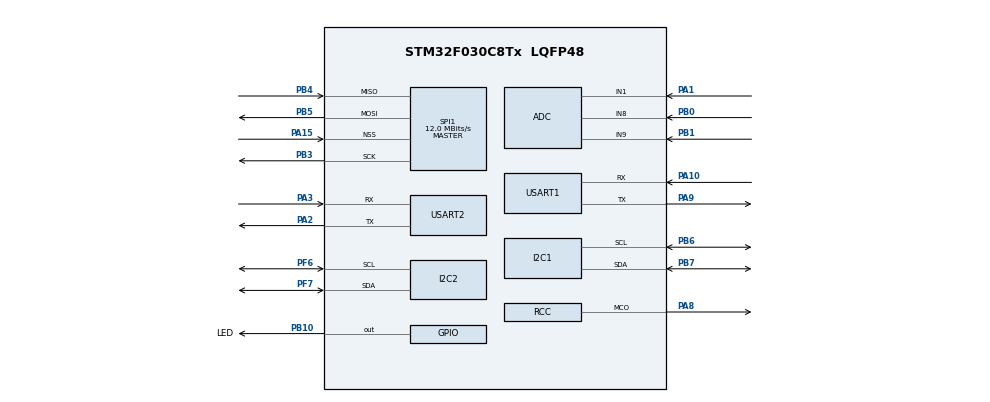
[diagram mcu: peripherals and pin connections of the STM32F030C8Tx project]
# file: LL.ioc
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I2C2.Timing=0x20303E5D
Mcu.Family=STM32F0
Mcu.Name=STM32F030C8Tx
Mcu.Package=LQFP48
PA1.Mode=IN1
PA1.Signal=ADC_IN1
PA10.Mode=Asynchronous
PA10.Signal=USART1_RX
PA13.Mode=Serial_Wire
PA13.Signal=SYS_SWDIO
PA14.Mode=Serial_Wire
PA14.Signal=SYS_SWCLK
PA15.Mode=NSS_Signal_Hard_Input
PA15.Signal=SPI1_NSS
PA2.Mode=Asynchronous
PA2.Signal=USART2_TX
PA3.Mode=Asynchronous
PA3.Signal=USART2_RX
PA8.Mode=Clock-out
PA8.Signal=RCC_MCO
PA9.Mode=Asynchronous
PA9.Signal=USART1_TX
PB0.Mode=IN8
PB0.Signal=ADC_IN8
PB1.Mode=IN9
PB1.Signal=ADC_IN9
PB10.GPIO_Label=LED
PB10.Signal=GPIO_Output
PB3.Mode=Full_Duplex_Master
PB3.Signal=SPI1_SCK
PB4.Mode=Full_Duplex_Master
PB4.Signal=SPI1_MISO
PB5.Mode=Full_Duplex_Master
PB5.Signal=SPI1_MOSI
PB6.Mode=I2C
PB6.Signal=I2C1_SCL
PB7.Mode=I2C
PB7.Signal=I2C1_SDA
PF0-OSC_IN.Mode=HSE-External-Oscillator
PF0-OSC_IN.Signal=RCC_OSC_IN
PF1-OSC_OUT.Mode=HSE-External-Oscillator
PF1-OSC_OUT.Signal=RCC_OSC_OUT
PF6.Mode=I2C
PF6.Signal=I2C2_SCL
PF7.Mode=I2C
PF7.Signal=I2C2_SDA
ProjectManager.HeapSize=0x200
ProjectManager.StackSize=0x400
ProjectManager.TargetToolchain=TrueSTUDIO
RCC.AHBFreq_Value=48000000
RCC.APB1Freq_Value=48000000
RCC.APB1TimFreq_Value=48000000
RCC.HCLKFreq_Value=48000000
RCC.PLLMUL=RCC_PLL_MUL12
RCC.RCC_MCOSource=RCC_MCO1SOURCE_PLLCLK_DIV2
RCC.SYSCLKFreq_VALUE=48000000
RCC.SYSCLKSource=RCC_SYSCLKSOURCE_PLLCLK
SPI1.BaudRatePrescaler=SPI_BAUDRATEPRESCALER_4
SPI1.CalculateBaudRate=12.0 MBits/s
SPI1.Direction=SPI_DIRECTION_2LINES
SPI1.Mode=SPI_MODE_MASTER
SPI1.VirtualNSS=VM_NSSHARD
SPI1.VirtualType=VM_MASTER
USART1.VirtualMode-Asynchronous=VM_ASYNC
USART2.VirtualMode-Asynchronous=VM_ASYNC
board=custom

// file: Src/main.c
/* USER CODE BEGIN Header */
/**
  ******************************************************************************
  * @file           : main.c
  * @brief          : Main program body
  ******************************************************************************
  * @attention
  *
  * <h2><center>&copy; Copyright (c) 2019 STMicroelectronics.
  * All rights reserved.</center></h2>
  *
  * This software component is licensed by ST under BSD 3-Clause license,
  * the "License"; You may not use this file except in compliance with the
  * License. You may obtain a copy of the License at:
  *                        opensource.org/licenses/BSD-3-Clause
  *
  ******************************************************************************
  */
/* USER CODE END Header */

#include "main.h"

void SystemClock_Config(void);
static void MX_GPIO_Init(void);
static void MX_ADC_Init(void);
static void MX_I2C1_Init(void);
static void MX_I2C2_Init(void);
static void MX_SPI1_Init(void);
static void MX_USART1_UART_Init(void);
static void MX_USART2_UART_Init(void);

int main(void)
{

  /* MCU Configuration--------------------------------------------------------*/

  /* Reset of all peripherals, Initializes the Flash interface and the Systick. */

  LL_APB1_GRP2_EnableClock(LL_APB1_GRP2_PERIPH_SYSCFG);
  LL_APB1_GRP1_EnableClock(LL_APB1_GRP1_PERIPH_PWR);

  /* System interrupt init*/

  /* Configure the system clock */
  SystemClock_Config();

  /* Initialize all configured peripherals */
  MX_GPIO_Init();
  MX_ADC_Init();
  MX_I2C1_Init();
  MX_I2C2_Init();
  MX_SPI1_Init();
  MX_USART1_UART_Init();
  MX_USART2_UART_Init();

  /* Infinite loop */
  while (1)
  {

    /* USER CODE BEGIN 3 */
	LL_GPIO_TogglePin(LED_GPIO_Port, LED_Pin);
	/* Insert delay 1000 ms */
	LL_mDelay(1000);
  }
  /* USER CODE END 3 */
}

void SystemClock_Config(void)
{
  LL_FLASH_SetLatency(LL_FLASH_LATENCY_1);

  if(LL_FLASH_GetLatency() != LL_FLASH_LATENCY_1)
  {
  Error_Handler();
  }
  LL_RCC_HSI_Enable();

   /* Wait till HSI is ready */
  while(LL_RCC_HSI_IsReady() != 1)
  {

  }
  LL_RCC_HSI_SetCalibTrimming(16);
  LL_RCC_HSI14_Enable();

   /* Wait till HSI14 is ready */
  while(LL_RCC_HSI14_IsReady() != 1)
  {

  }
  LL_RCC_HSI14_SetCalibTrimming(16);
  LL_RCC_PLL_ConfigDomain_SYS(LL_RCC_PLLSOURCE_HSI_DIV_2, LL_RCC_PLL_MUL_12);
  LL_RCC_PLL_Enable();

   /* Wait till PLL is ready */
  while(LL_RCC_PLL_IsReady() != 1)
  {

  }
  LL_RCC_SetAHBPrescaler(LL_RCC_SYSCLK_DIV_1);
  LL_RCC_SetAPB1Prescaler(LL_RCC_APB1_DIV_1);
  LL_RCC_SetSysClkSource(LL_RCC_SYS_CLKSOURCE_PLL);

   /* Wait till System clock is ready */
  while(LL_RCC_GetSysClkSource() != LL_RCC_SYS_CLKSOURCE_STATUS_PLL)
  {

  }
  LL_Init1msTick(48000000);
  LL_SYSTICK_SetClkSource(LL_SYSTICK_CLKSOURCE_HCLK);
  LL_SetSystemCoreClock(48000000);
  LL_RCC_HSI14_EnableADCControl();
  LL_RCC_SetUSARTClockSource(LL_RCC_USART1_CLKSOURCE_PCLK1);
  LL_RCC_SetI2CClockSource(LL_RCC_I2C1_CLKSOURCE_HSI);
  LL_RCC_ConfigMCO(LL_RCC_MCO1SOURCE_PLLCLK_DIV_2, LL_RCC_MCO1_DIV_1);
}

static void MX_ADC_Init(void)
{

  LL_ADC_InitTypeDef ADC_InitStruct = {0};
  LL_ADC_REG_InitTypeDef ADC_REG_InitStruct = {0};

  LL_GPIO_InitTypeDef GPIO_InitStruct = {0};

  /* Peripheral clock enable */
  LL_APB1_GRP2_EnableClock(LL_APB1_GRP2_PERIPH_ADC1);

  LL_AHB1_GRP1_EnableClock(LL_AHB1_GRP1_PERIPH_GPIOA);
  LL_AHB1_GRP1_EnableClock(LL_AHB1_GRP1_PERIPH_GPIOB);
  /**ADC GPIO Configuration
  PA1   ------> ADC_IN1
  PB0   ------> ADC_IN8
  PB1   ------> ADC_IN9
  */
  GPIO_InitStruct.Pin = LL_GPIO_PIN_1;
  GPIO_InitStruct.Mode = LL_GPIO_MODE_ANALOG;
  GPIO_InitStruct.Pull = LL_GPIO_PULL_NO;
  LL_GPIO_Init(GPIOA, &GPIO_InitStruct);

  GPIO_InitStruct.Pin = LL_GPIO_PIN_0;
  GPIO_InitStruct.Mode = LL_GPIO_MODE_ANALOG;
  GPIO_InitStruct.Pull = LL_GPIO_PULL_NO;
  LL_GPIO_Init(GPIOB, &GPIO_InitStruct);

  GPIO_InitStruct.Pin = LL_GPIO_PIN_1;
  GPIO_InitStruct.Mode = LL_GPIO_MODE_ANALOG;
  GPIO_InitStruct.Pull = LL_GPIO_PULL_NO;
  LL_GPIO_Init(GPIOB, &GPIO_InitStruct);

  /** Configure Regular Channel
  */
  LL_ADC_REG_SetSequencerChAdd(ADC1, LL_ADC_CHANNEL_1);
  /** Configure Regular Channel
  */
  LL_ADC_REG_SetSequencerChAdd(ADC1, LL_ADC_CHANNEL_8);
  /** Configure Regular Channel
  */
  LL_ADC_REG_SetSequencerChAdd(ADC1, LL_ADC_CHANNEL_9);
  /** Configure the global features of the ADC (Clock, Resolution, Data Alignment and number of conversion)
  */
  ADC_InitStruct.Clock = LL_ADC_CLOCK_ASYNC;
  ADC_InitStruct.Resolution = LL_ADC_RESOLUTION_12B;
  ADC_InitStruct.DataAlignment = LL_ADC_DATA_ALIGN_RIGHT;
  ADC_InitStruct.LowPowerMode = LL_ADC_LP_MODE_NONE;
  LL_ADC_Init(ADC1, &ADC_InitStruct);
  ADC_REG_InitStruct.TriggerSource = LL_ADC_REG_TRIG_SOFTWARE;
  ADC_REG_InitStruct.SequencerDiscont = LL_ADC_REG_SEQ_DISCONT_DISABLE;
  ADC_REG_InitStruct.ContinuousMode = LL_ADC_REG_CONV_SINGLE;
  ADC_REG_InitStruct.DMATransfer = LL_ADC_REG_DMA_TRANSFER_LIMITED;
  ADC_REG_InitStruct.Overrun = LL_ADC_REG_OVR_DATA_PRESERVED;
  LL_ADC_REG_Init(ADC1, &ADC_REG_InitStruct);
  LL_ADC_REG_SetSequencerScanDirection(ADC1, LL_ADC_REG_SEQ_SCAN_DIR_FORWARD);
  LL_ADC_SetSamplingTimeCommonChannels(ADC1, LL_ADC_SAMPLINGTIME_1CYCLE_5);
  LL_ADC_DisableIT_EOC(ADC1);
  LL_ADC_DisableIT_EOS(ADC1);

}

static void MX_I2C1_Init(void)
{

  LL_I2C_InitTypeDef I2C_InitStruct = {0};

  LL_GPIO_InitTypeDef GPIO_InitStruct = {0};

  LL_AHB1_GRP1_EnableClock(LL_AHB1_GRP1_PERIPH_GPIOB);
  /**I2C1 GPIO Configuration
  PB6   ------> I2C1_SCL
  PB7   ------> I2C1_SDA
  */
  GPIO_InitStruct.Pin = LL_GPIO_PIN_6;
  GPIO_InitStruct.Mode = LL_GPIO_MODE_ALTERNATE;
  GPIO_InitStruct.Speed = LL_GPIO_SPEED_FREQ_HIGH;
  GPIO_InitStruct.OutputType = LL_GPIO_OUTPUT_OPENDRAIN;
  GPIO_InitStruct.Pull = LL_GPIO_PULL_UP;
  GPIO_InitStruct.Alternate = LL_GPIO_AF_1;
  LL_GPIO_Init(GPIOB, &GPIO_InitStruct);

  GPIO_InitStruct.Pin = LL_GPIO_PIN_7;
  GPIO_InitStruct.Mode = LL_GPIO_MODE_ALTERNATE;
  GPIO_InitStruct.Speed = LL_GPIO_SPEED_FREQ_HIGH;
  GPIO_InitStruct.OutputType = LL_GPIO_OUTPUT_OPENDRAIN;
  GPIO_InitStruct.Pull = LL_GPIO_PULL_UP;
  GPIO_InitStruct.Alternate = LL_GPIO_AF_1;
  LL_GPIO_Init(GPIOB, &GPIO_InitStruct);

  /* Peripheral clock enable */
  LL_APB1_GRP1_EnableClock(LL_APB1_GRP1_PERIPH_I2C1);

  /** I2C Initialization
  */
  LL_I2C_DisableOwnAddress2(I2C1);
  LL_I2C_DisableGeneralCall(I2C1);
  LL_I2C_EnableClockStretching(I2C1);
  I2C_InitStruct.PeripheralMode = LL_I2C_MODE_I2C;
  I2C_InitStruct.Timing = 0x2000090E;
  I2C_InitStruct.AnalogFilter = LL_I2C_ANALOGFILTER_ENABLE;
  I2C_InitStruct.DigitalFilter = 0;
  I2C_InitStruct.OwnAddress1 = 0;
  I2C_InitStruct.TypeAcknowledge = LL_I2C_ACK;
  I2C_InitStruct.OwnAddrSize = LL_I2C_OWNADDRESS1_7BIT;
  LL_I2C_Init(I2C1, &I2C_InitStruct);
  LL_I2C_EnableAutoEndMode(I2C1);
  LL_I2C_SetOwnAddress2(I2C1, 0, LL_I2C_OWNADDRESS2_NOMASK);

}

static void MX_I2C2_Init(void)
{

  LL_I2C_InitTypeDef I2C_InitStruct = {0};

  LL_GPIO_InitTypeDef GPIO_InitStruct = {0};

  LL_AHB1_GRP1_EnableClock(LL_AHB1_GRP1_PERIPH_GPIOF);
  /**I2C2 GPIO Configuration
  PF6   ------> I2C2_SCL
  PF7   ------> I2C2_SDA
  */
  GPIO_InitStruct.Pin = LL_GPIO_PIN_6;
  GPIO_InitStruct.Mode = LL_GPIO_MODE_ALTERNATE;
  GPIO_InitStruct.Speed = LL_GPIO_SPEED_FREQ_HIGH;
  GPIO_InitStruct.OutputType = LL_GPIO_OUTPUT_OPENDRAIN;
  GPIO_InitStruct.Pull = LL_GPIO_PULL_UP;
  LL_GPIO_Init(GPIOF, &GPIO_InitStruct);

  GPIO_InitStruct.Pin = LL_GPIO_PIN_7;
  GPIO_InitStruct.Mode = LL_GPIO_MODE_ALTERNATE;
  GPIO_InitStruct.Speed = LL_GPIO_SPEED_FREQ_HIGH;
  GPIO_InitStruct.OutputType = LL_GPIO_OUTPUT_OPENDRAIN;
  GPIO_InitStruct.Pull = LL_GPIO_PULL_UP;
  LL_GPIO_Init(GPIOF, &GPIO_InitStruct);

  /* Peripheral clock enable */
  LL_APB1_GRP1_EnableClock(LL_APB1_GRP1_PERIPH_I2C2);

  /** I2C Initialization
  */
  LL_I2C_DisableOwnAddress2(I2C2);
  LL_I2C_DisableGeneralCall(I2C2);
  LL_I2C_EnableClockStretching(I2C2);
  I2C_InitStruct.PeripheralMode = LL_I2C_MODE_I2C;
  I2C_InitStruct.Timing = 0x20303E5D;
  I2C_InitStruct.AnalogFilter = LL_I2C_ANALOGFILTER_ENABLE;
  I2C_InitStruct.DigitalFilter = 0;
  I2C_InitStruct.OwnAddress1 = 0;
  I2C_InitStruct.TypeAcknowledge = LL_I2C_ACK;
  I2C_InitStruct.OwnAddrSize = LL_I2C_OWNADDRESS1_7BIT;
  LL_I2C_Init(I2C2, &I2C_InitStruct);
  LL_I2C_EnableAutoEndMode(I2C2);
  LL_I2C_SetOwnAddress2(I2C2, 0, LL_I2C_OWNADDRESS2_NOMASK);

}

static void MX_SPI1_Init(void)
{

  LL_SPI_InitTypeDef SPI_InitStruct = {0};

  LL_GPIO_InitTypeDef GPIO_InitStruct = {0};

  /* Peripheral clock enable */
  LL_APB1_GRP2_EnableClock(LL_APB1_GRP2_PERIPH_SPI1);

  LL_AHB1_GRP1_EnableClock(LL_AHB1_GRP1_PERIPH_GPIOA);
  LL_AHB1_GRP1_EnableClock(LL_AHB1_GRP1_PERIPH_GPIOB);
  /**SPI1 GPIO Configuration
  PA15   ------> SPI1_NSS
  PB3   ------> SPI1_SCK
  PB4   ------> SPI1_MISO
  PB5   ------> SPI1_MOSI
  */
  GPIO_InitStruct.Pin = LL_GPIO_PIN_15;
  GPIO_InitStruct.Mode = LL_GPIO_MODE_ALTERNATE;
  GPIO_InitStruct.Speed = LL_GPIO_SPEED_FREQ_HIGH;
  GPIO_InitStruct.OutputType = LL_GPIO_OUTPUT_PUSHPULL;
  GPIO_InitStruct.Pull = LL_GPIO_PULL_NO;
  GPIO_InitStruct.Alternate = LL_GPIO_AF_0;
  LL_GPIO_Init(GPIOA, &GPIO_InitStruct);

  GPIO_InitStruct.Pin = LL_GPIO_PIN_3;
  GPIO_InitStruct.Mode = LL_GPIO_MODE_ALTERNATE;
  GPIO_InitStruct.Speed = LL_GPIO_SPEED_FREQ_HIGH;
  GPIO_InitStruct.OutputType = LL_GPIO_OUTPUT_PUSHPULL;
  GPIO_InitStruct.Pull = LL_GPIO_PULL_NO;
  GPIO_InitStruct.Alternate = LL_GPIO_AF_0;
  LL_GPIO_Init(GPIOB, &GPIO_InitStruct);

  GPIO_InitStruct.Pin = LL_GPIO_PIN_4;
  GPIO_InitStruct.Mode = LL_GPIO_MODE_ALTERNATE;
  GPIO_InitStruct.Speed = LL_GPIO_SPEED_FREQ_HIGH;
  GPIO_InitStruct.OutputType = LL_GPIO_OUTPUT_PUSHPULL;
  GPIO_InitStruct.Pull = LL_GPIO_PULL_NO;
  GPIO_InitStruct.Alternate = LL_GPIO_AF_0;
  LL_GPIO_Init(GPIOB, &GPIO_InitStruct);

  GPIO_InitStruct.Pin = LL_GPIO_PIN_5;
  GPIO_InitStruct.Mode = LL_GPIO_MODE_ALTERNATE;
  GPIO_InitStruct.Speed = LL_GPIO_SPEED_FREQ_HIGH;
  GPIO_InitStruct.OutputType = LL_GPIO_OUTPUT_PUSHPULL;
  GPIO_InitStruct.Pull = LL_GPIO_PULL_NO;
  GPIO_InitStruct.Alternate = LL_GPIO_AF_0;
  LL_GPIO_Init(GPIOB, &GPIO_InitStruct);

  /* SPI1 parameter configuration*/
  SPI_InitStruct.TransferDirection = LL_SPI_FULL_DUPLEX;
  SPI_InitStruct.Mode = LL_SPI_MODE_MASTER;
  SPI_InitStruct.DataWidth = LL_SPI_DATAWIDTH_4BIT;
  SPI_InitStruct.ClockPolarity = LL_SPI_POLARITY_LOW;
  SPI_InitStruct.ClockPhase = LL_SPI_PHASE_1EDGE;
  SPI_InitStruct.NSS = LL_SPI_NSS_HARD_INPUT;
  SPI_InitStruct.BaudRate = LL_SPI_BAUDRATEPRESCALER_DIV4;
  SPI_InitStruct.BitOrder = LL_SPI_MSB_FIRST;
  SPI_InitStruct.CRCCalculation = LL_SPI_CRCCALCULATION_DISABLE;
  SPI_InitStruct.CRCPoly = 7;
  LL_SPI_Init(SPI1, &SPI_InitStruct);
  LL_SPI_SetStandard(SPI1, LL_SPI_PROTOCOL_MOTOROLA);
  LL_SPI_EnableNSSPulseMgt(SPI1);

}

static void MX_USART1_UART_Init(void)
{

  LL_USART_InitTypeDef USART_InitStruct = {0};

  LL_GPIO_InitTypeDef GPIO_InitStruct = {0};

  /* Peripheral clock enable */
  LL_APB1_GRP2_EnableClock(LL_APB1_GRP2_PERIPH_USART1);

  LL_AHB1_GRP1_EnableClock(LL_AHB1_GRP1_PERIPH_GPIOA);
  /**USART1 GPIO Configuration
  PA9   ------> USART1_TX
  PA10   ------> USART1_RX
  */
  GPIO_InitStruct.Pin = LL_GPIO_PIN_9;
  GPIO_InitStruct.Mode = LL_GPIO_MODE_ALTERNATE;
  GPIO_InitStruct.Speed = LL_GPIO_SPEED_FREQ_HIGH;
  GPIO_InitStruct.OutputType = LL_GPIO_OUTPUT_PUSHPULL;
  GPIO_InitStruct.Pull = LL_GPIO_PULL_NO;
  GPIO_InitStruct.Alternate = LL_GPIO_AF_1;
  LL_GPIO_Init(GPIOA, &GPIO_InitStruct);

  GPIO_InitStruct.Pin = LL_GPIO_PIN_10;
  GPIO_InitStruct.Mode = LL_GPIO_MODE_ALTERNATE;
  GPIO_InitStruct.Speed = LL_GPIO_SPEED_FREQ_HIGH;
  GPIO_InitStruct.OutputType = LL_GPIO_OUTPUT_PUSHPULL;
  GPIO_InitStruct.Pull = LL_GPIO_PULL_NO;
  GPIO_InitStruct.Alternate = LL_GPIO_AF_1;
  LL_GPIO_Init(GPIOA, &GPIO_InitStruct);

  USART_InitStruct.BaudRate = 38400;
  USART_InitStruct.DataWidth = LL_USART_DATAWIDTH_8B;
  USART_InitStruct.StopBits = LL_USART_STOPBITS_1;
  USART_InitStruct.Parity = LL_USART_PARITY_NONE;
  USART_InitStruct.TransferDirection = LL_USART_DIRECTION_TX_RX;
  USART_InitStruct.HardwareFlowControl = LL_USART_HWCONTROL_NONE;
  USART_InitStruct.OverSampling = LL_USART_OVERSAMPLING_16;
  LL_USART_Init(USART1, &USART_InitStruct);
  LL_USART_DisableIT_CTS(USART1);
  LL_USART_DisableOverrunDetect(USART1);
  LL_USART_ConfigAsyncMode(USART1);
  LL_USART_Enable(USART1);

}

static void MX_USART2_UART_Init(void)
{

  LL_USART_InitTypeDef USART_InitStruct = {0};

  LL_GPIO_InitTypeDef GPIO_InitStruct = {0};

  /* Peripheral clock enable */
  LL_APB1_GRP1_EnableClock(LL_APB1_GRP1_PERIPH_USART2);

  LL_AHB1_GRP1_EnableClock(LL_AHB1_GRP1_PERIPH_GPIOA);
  /**USART2 GPIO Configuration
  PA2   ------> USART2_TX
  PA3   ------> USART2_RX
  */
  GPIO_InitStruct.Pin = LL_GPIO_PIN_2;
  GPIO_InitStruct.Mode = LL_GPIO_MODE_ALTERNATE;
  GPIO_InitStruct.Speed = LL_GPIO_SPEED_FREQ_HIGH;
  GPIO_InitStruct.OutputType = LL_GPIO_OUTPUT_PUSHPULL;
  GPIO_InitStruct.Pull = LL_GPIO_PULL_NO;
  GPIO_InitStruct.Alternate = LL_GPIO_AF_1;
  LL_GPIO_Init(GPIOA, &GPIO_InitStruct);

  GPIO_InitStruct.Pin = LL_GPIO_PIN_3;
  GPIO_InitStruct.Mode = LL_GPIO_MODE_ALTERNATE;
  GPIO_InitStruct.Speed = LL_GPIO_SPEED_FREQ_HIGH;
  GPIO_InitStruct.OutputType = LL_GPIO_OUTPUT_PUSHPULL;
  GPIO_InitStruct.Pull = LL_GPIO_PULL_NO;
  GPIO_InitStruct.Alternate = LL_GPIO_AF_1;
  LL_GPIO_Init(GPIOA, &GPIO_InitStruct);

  USART_InitStruct.BaudRate = 38400;
  USART_InitStruct.DataWidth = LL_USART_DATAWIDTH_8B;
  USART_InitStruct.StopBits = LL_USART_STOPBITS_1;
  USART_InitStruct.Parity = LL_USART_PARITY_NONE;
  USART_InitStruct.TransferDirection = LL_USART_DIRECTION_TX_RX;
  USART_InitStruct.HardwareFlowControl = LL_USART_HWCONTROL_NONE;
  USART_InitStruct.OverSampling = LL_USART_OVERSAMPLING_16;
  LL_USART_Init(USART2, &USART_InitStruct);
  LL_USART_DisableIT_CTS(USART2);
  LL_USART_DisableOverrunDetect(USART2);
  LL_USART_ConfigAsyncMode(USART2);
  LL_USART_Enable(USART2);

}

static void MX_GPIO_Init(void)
{
  LL_GPIO_InitTypeDef GPIO_InitStruct = {0};

  /* GPIO Ports Clock Enable */
  LL_AHB1_GRP1_EnableClock(LL_AHB1_GRP1_PERIPH_GPIOF);
  LL_AHB1_GRP1_EnableClock(LL_AHB1_GRP1_PERIPH_GPIOA);
  LL_AHB1_GRP1_EnableClock(LL_AHB1_GRP1_PERIPH_GPIOB);

  /**/
  LL_GPIO_ResetOutputPin(LED_GPIO_Port, LED_Pin);

  /**/
  GPIO_InitStruct.Pin = LED_Pin;
  GPIO_InitStruct.Mode = LL_GPIO_MODE_OUTPUT;
  GPIO_InitStruct.Speed = LL_GPIO_SPEED_FREQ_LOW;
  GPIO_InitStruct.OutputType = LL_GPIO_OUTPUT_PUSHPULL;
  GPIO_InitStruct.Pull = LL_GPIO_PULL_NO;
  LL_GPIO_Init(LED_GPIO_Port, &GPIO_InitStruct);

  /**/
  GPIO_InitStruct.Pin = LL_GPIO_PIN_8;
  GPIO_InitStruct.Mode = LL_GPIO_MODE_ALTERNATE;
  GPIO_InitStruct.Speed = LL_GPIO_SPEED_FREQ_LOW;
  GPIO_InitStruct.OutputType = LL_GPIO_OUTPUT_PUSHPULL;
  GPIO_InitStruct.Pull = LL_GPIO_PULL_NO;
  GPIO_InitStruct.Alternate = LL_GPIO_AF_0;
  LL_GPIO_Init(GPIOA, &GPIO_InitStruct);

}

void Error_Handler(void)
{
}

/************************ (C) COPYRIGHT STMicroelectronics *****END OF FILE****/
